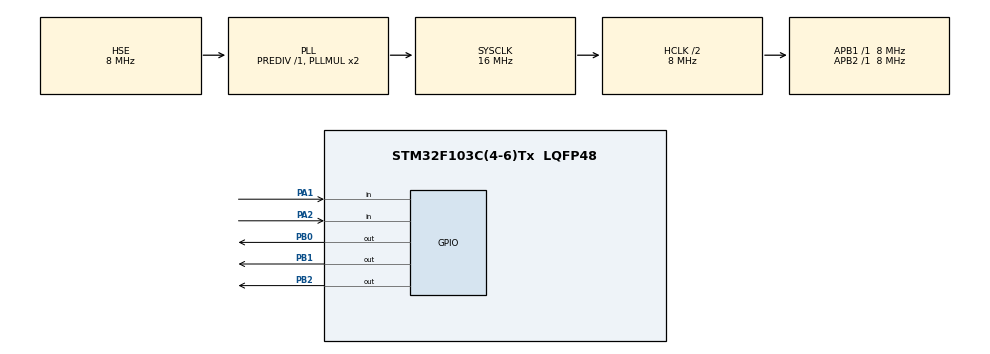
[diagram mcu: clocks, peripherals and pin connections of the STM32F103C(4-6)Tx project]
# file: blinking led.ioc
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Mcu.Family=STM32F1
Mcu.Name=STM32F103C(4-6)Tx
Mcu.Package=LQFP48
NVIC.PriorityGroup=NVIC_PRIORITYGROUP_4
PA1.Signal=GPIO_Input
PA2.Signal=GPIO_Input
PB0.GPIO_PuPd=GPIO_PULLUP
PB0.Signal=GPIO_Output
PB1.GPIO_PuPd=GPIO_PULLUP
PB1.Signal=GPIO_Output
PB2.GPIO_PuPd=GPIO_PULLUP
PB2.Signal=GPIO_Output
PD0-OSC_IN.Mode=HSE-External-Oscillator
PD0-OSC_IN.Signal=RCC_OSC_IN
PD1-OSC_OUT.Mode=HSE-External-Oscillator
PD1-OSC_OUT.Signal=RCC_OSC_OUT
ProjectManager.HeapSize=0x200
ProjectManager.StackSize=0x400
ProjectManager.TargetToolchain=STM32CubeIDE
RCC.AHBCLKDivider=RCC_SYSCLK_DIV2
RCC.AHBFreq_Value=8000000
RCC.APB1Freq_Value=8000000
RCC.APB1TimFreq_Value=8000000
RCC.APB2Freq_Value=8000000
RCC.APB2TimFreq_Value=8000000
RCC.EnbaleCSS=true
RCC.HCLKFreq_Value=8000000
RCC.PLLSourceVirtual=RCC_PLLSOURCE_HSE
RCC.SYSCLKFreq_VALUE=16000000
RCC.SYSCLKSource=RCC_SYSCLKSOURCE_PLLCLK
RCC.USBFreq_Value=16000000
board=custom

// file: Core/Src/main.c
/* USER CODE BEGIN Header */
/**
 ******************************************************************************
 * @file           : main.c
 * @brief          : Main program body
 ******************************************************************************
 * @attention
 *
 * Copyright (c) 2022 STMicroelectronics.
 * All rights reserved.
 *
 * This software is licensed under terms that can be found in the LICENSE file
 * in the root directory of this software component.
 * If no LICENSE file comes with this software, it is provided AS-IS.
 *
 ******************************************************************************
 */
/* USER CODE END Header */
#include "main.h"

#define BUTTON1_PORT 	GPIOA
#define BUTTON1_PIN		GPIO_PIN_1

#define BUTTON2_PORT	GPIOA
#define BUTTON2_PIN		GPIO_PIN_2

#define LED1_PORT		GPIOB
#define LED1_PIN		GPIO_PIN_0

#define LED2_PORT		GPIOB
#define LED2_PIN		GPIO_PIN_1

#define LED3_PORT		GPIOB
#define LED3_PIN		GPIO_PIN_2

void SystemClock_Config(void);
static void MX_GPIO_Init(void);

int main(void)
{

	/* USER CODE BEGIN 1 */
	/* defining a variable to store the current led state */
	unsigned char button1_counter =0;
	/* USER CODE END 1 */

	/* MCU Configuration--------------------------------------------------------*/

	/* Reset of all peripherals, Initializes the Flash interface and the Systick. */
	HAL_Init();

	/* Configure the system clock */
	SystemClock_Config();

	/* Initialize all configured peripherals */
	MX_GPIO_Init();

	/* Infinite loop */
	/* USER CODE BEGIN WHILE */
	while (1)
	{
		if (HAL_GPIO_ReadPin (BUTTON1_PORT, BUTTON1_PIN))
		{
			/* to avoid de-bouncing */
			HAL_Delay(30);

			if (HAL_GPIO_ReadPin (BUTTON1_PORT, BUTTON1_PIN))
			{
				switch (button1_counter)
				{
				case 0:
					HAL_GPIO_WritePin(LED1_PORT, LED1_PIN, GPIO_PIN_SET);
					HAL_GPIO_WritePin(LED2_PORT, LED2_PIN, GPIO_PIN_RESET);
					HAL_GPIO_WritePin(LED3_PORT, LED3_PIN, GPIO_PIN_RESET);
					button1_counter++;
					break;
				case 1:
					HAL_GPIO_WritePin(LED1_PORT, LED1_PIN, GPIO_PIN_RESET);
					HAL_GPIO_WritePin(LED2_PORT, LED2_PIN, GPIO_PIN_SET);
					HAL_GPIO_WritePin(LED3_PORT, LED3_PIN, GPIO_PIN_RESET);
					button1_counter++;
					break;
				case 2:
					HAL_GPIO_WritePin(LED1_PORT, LED1_PIN, GPIO_PIN_RESET);
					HAL_GPIO_WritePin(LED2_PORT, LED2_PIN, GPIO_PIN_RESET);
					HAL_GPIO_WritePin(LED3_PORT, LED3_PIN, GPIO_PIN_SET);
					button1_counter=0;
					break;
				}
			}
		}

		if (HAL_GPIO_ReadPin (BUTTON2_PORT, BUTTON2_PIN))
		{
			/* to avoid de-bouncing */
			HAL_Delay(30);
			if (HAL_GPIO_ReadPin (BUTTON2_PORT, BUTTON2_PIN))
			{
				HAL_GPIO_TogglePin(LED1_PORT, LED1_PIN);
				HAL_GPIO_TogglePin(LED2_PORT, LED2_PIN);
				HAL_GPIO_TogglePin(LED3_PORT, LED3_PIN);
			}
		}

		/* to avoid incrementing two state with only one small push on the button
		 * but in the same time, in case of long push the states will increment*/
		HAL_Delay(50);
	}
	/* USER CODE END 3 */
}

void SystemClock_Config(void)
{
	RCC_OscInitTypeDef RCC_OscInitStruct = {0};
	RCC_ClkInitTypeDef RCC_ClkInitStruct = {0};

	/** Initializes the RCC Oscillators according to the specified parameters
	 * in the RCC_OscInitTypeDef structure.
	 */
	RCC_OscInitStruct.OscillatorType = RCC_OSCILLATORTYPE_HSE;
	RCC_OscInitStruct.HSEState = RCC_HSE_ON;
	RCC_OscInitStruct.HSEPredivValue = RCC_HSE_PREDIV_DIV1;
	RCC_OscInitStruct.HSIState = RCC_HSI_ON;
	RCC_OscInitStruct.PLL.PLLState = RCC_PLL_ON;
	RCC_OscInitStruct.PLL.PLLSource = RCC_PLLSOURCE_HSE;
	RCC_OscInitStruct.PLL.PLLMUL = RCC_PLL_MUL2;
	if (HAL_RCC_OscConfig(&RCC_OscInitStruct) != HAL_OK)
	{
		Error_Handler();
	}

	/** Initializes the CPU, AHB and APB buses clocks
	 */
	RCC_ClkInitStruct.ClockType = RCC_CLOCKTYPE_HCLK|RCC_CLOCKTYPE_SYSCLK
			|RCC_CLOCKTYPE_PCLK1|RCC_CLOCKTYPE_PCLK2;
	RCC_ClkInitStruct.SYSCLKSource = RCC_SYSCLKSOURCE_PLLCLK;
	RCC_ClkInitStruct.AHBCLKDivider = RCC_SYSCLK_DIV2;
	RCC_ClkInitStruct.APB1CLKDivider = RCC_HCLK_DIV1;
	RCC_ClkInitStruct.APB2CLKDivider = RCC_HCLK_DIV1;

	if (HAL_RCC_ClockConfig(&RCC_ClkInitStruct, FLASH_LATENCY_0) != HAL_OK)
	{
		Error_Handler();
	}

	/** Enables the Clock Security System
	 */
	HAL_RCC_EnableCSS();
}

static void MX_GPIO_Init(void)
{
	GPIO_InitTypeDef GPIO_InitStruct = {0};

	/* GPIO Ports Clock Enable */
	__HAL_RCC_GPIOD_CLK_ENABLE();
	__HAL_RCC_GPIOA_CLK_ENABLE();
	__HAL_RCC_GPIOB_CLK_ENABLE();

	/*Configure GPIO pin Output Level */
	HAL_GPIO_WritePin(GPIOB, GPIO_PIN_0|GPIO_PIN_1|GPIO_PIN_2, GPIO_PIN_RESET);

	/*Configure GPIO pins : PA1 PA2 */
	GPIO_InitStruct.Pin = GPIO_PIN_1|GPIO_PIN_2;
	GPIO_InitStruct.Mode = GPIO_MODE_INPUT;
	GPIO_InitStruct.Pull = GPIO_NOPULL;
	HAL_GPIO_Init(GPIOA, &GPIO_InitStruct);

	/*Configure GPIO pins : PB0 PB1 PB2 */
	GPIO_InitStruct.Pin = GPIO_PIN_0|GPIO_PIN_1|GPIO_PIN_2;
	GPIO_InitStruct.Mode = GPIO_MODE_OUTPUT_PP;
	GPIO_InitStruct.Pull = GPIO_PULLUP;
	GPIO_InitStruct.Speed = GPIO_SPEED_FREQ_LOW;
	HAL_GPIO_Init(GPIOB, &GPIO_InitStruct);

}

void Error_Handler(void)
{
	__disable_irq();
	while (1)
	{
	}
}
